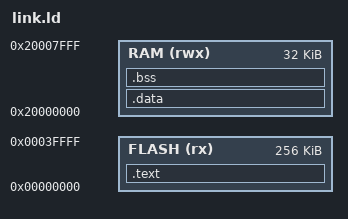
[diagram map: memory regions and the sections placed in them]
MEMORY
{
    FLASH (rx) : ORIGIN = 0x00000000, LENGTH = 256K
    RAM (rwx)  : ORIGIN = 0x20000000, LENGTH = 32K
}

SECTIONS
{
    .text :
    {
        _text = .;
        KEEP(*(.isr_vector))
        *(.text*)
        *(.rodata*)
        _etext = .;
    } > FLASH

    .data : AT(_etext)
    {
        _data = .;
        *(.data*)
        _edata = .;
    } > RAM

    .bss :
    {
        _bss = .;
        *(.bss*)
        *(COMMON)
        _ebss = .;
    } > RAM

    /* Set the stack to the end of RAM */
    __stack_top = ORIGIN(RAM) + LENGTH(RAM);
}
